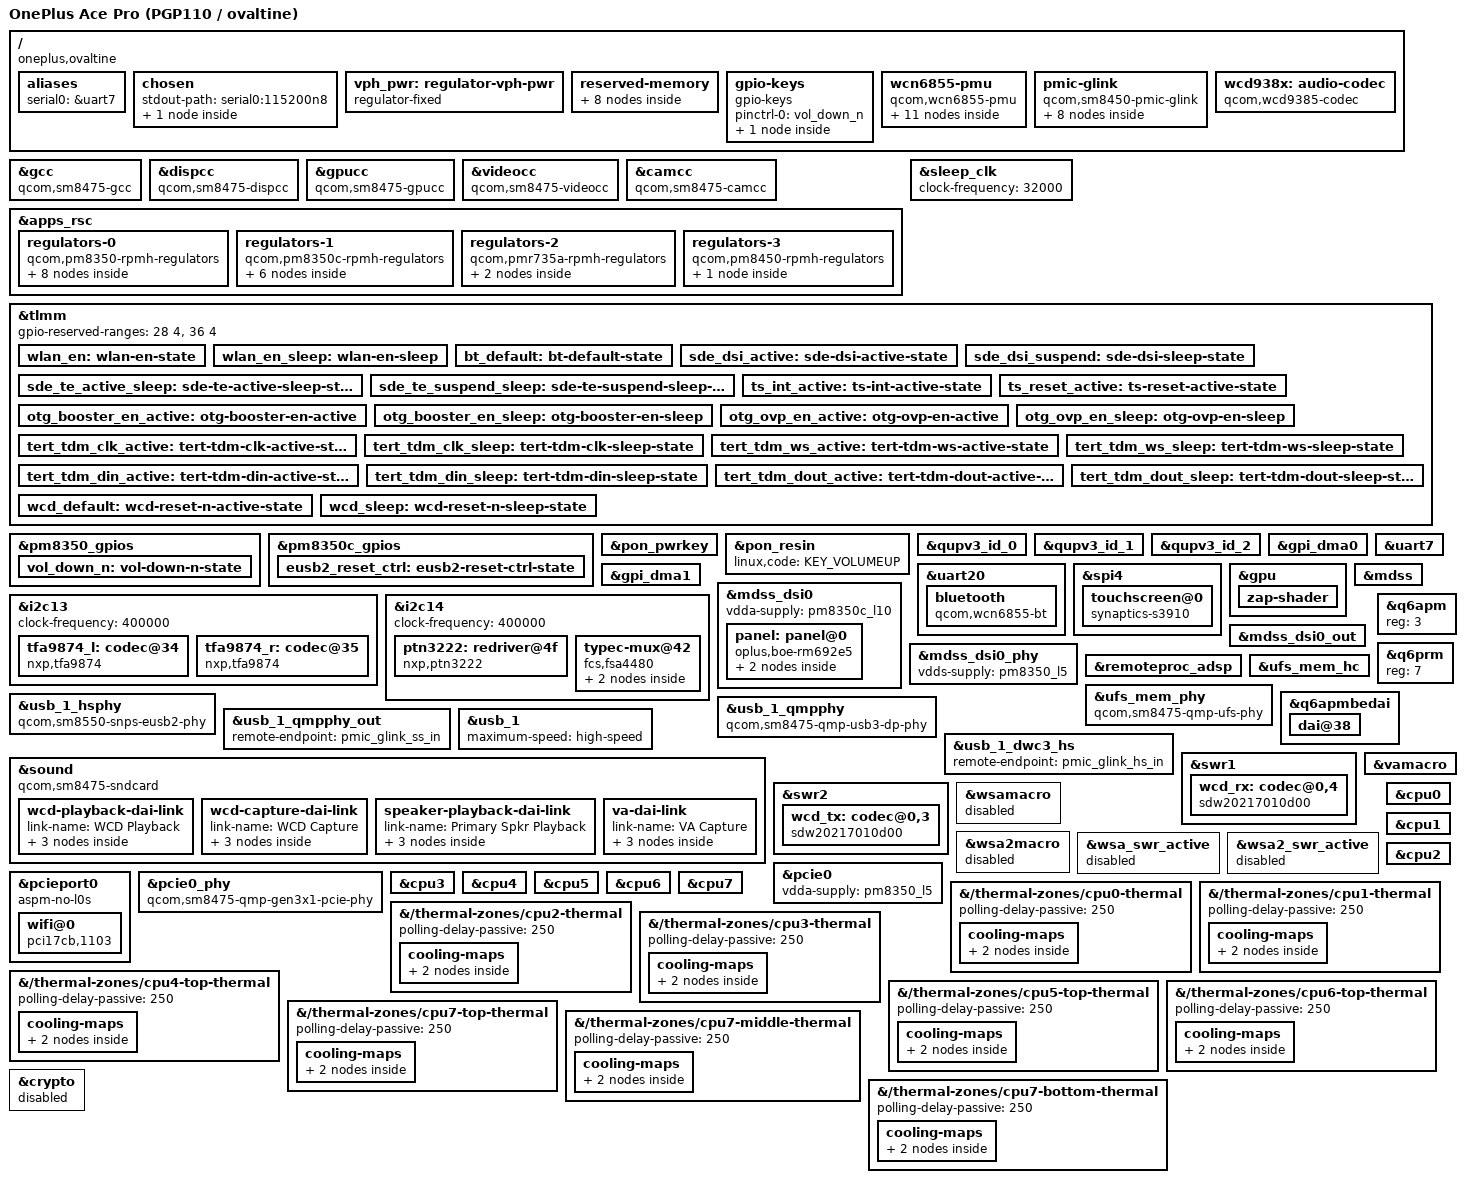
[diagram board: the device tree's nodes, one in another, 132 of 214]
// SPDX-License-Identifier: GPL-2.0-only
/*
 * P1 mainline Device Tree for OnePlus Ace Pro (PGP110 / ovaltine, SM8475).
 */

/dts-v1/;

#include <dt-bindings/arm/qcom,ids.h>
#include <dt-bindings/gpio/gpio.h>
#include <dt-bindings/input/linux-event-codes.h>
#include <dt-bindings/interrupt-controller/irq.h>
#include <dt-bindings/pinctrl/qcom,pmic-gpio.h>
#include <dt-bindings/regulator/qcom,rpmh-regulator.h>

#include "sm8450.dtsi"
#include "pm8350.dtsi"
#include "pm8350b.dtsi"
#include "pm8350c.dtsi"
#include "pm8450.dtsi"
#include "pmk8350.dtsi"
#include "pmr735a.dtsi"

/delete-node/ &cdsp_secure_heap;
/delete-node/ &video_mem;
/delete-node/ &adsp_mem;
/delete-node/ &slpi_mem;
/delete-node/ &rmtfs_mem;

/ {
	model = "OnePlus Ace Pro (PGP110 / ovaltine)";
	compatible = "oneplus,ovaltine", "qcom,sm8475", "qcom,sm8450";
	chassis-type = "handset";

	/* ABL board matching IDs (also provided in sm8475-ovaltine.dtbo) */
	qcom,msm-id = <0x213 0x10000 0x21c 0x10000 0x212 0x10000>;
	qcom,board-id = <0x10008 0x00>;
	oplus,project-id = <0x5552 0x5551>;
	oplus,region-id = <0x01 0x02>;

	aliases {
		serial0 = &uart7;
	};

	chosen {
		#address-cells = <2>;
		#size-cells = <2>;
		ranges;

		stdout-path = "serial0:115200n8";

		framebuffer: framebuffer@b8000000 {
			compatible = "simple-framebuffer";
			reg = <0x0 0xb8000000 0x0 0x2b00000>;
			width = <1080>;
			height = <2412>;
			stride = <(1080 * 4)>;
			format = "a8r8g8b8";
		};
	};

	vph_pwr: regulator-vph-pwr {
		compatible = "regulator-fixed";
		regulator-name = "vph_pwr";
		regulator-min-microvolt = <3700000>;
		regulator-max-microvolt = <3700000>;
		regulator-always-on;
		regulator-boot-on;
	};

	reserved-memory {
		cdsp_secure_heap: memory@80c00000 {
			reg = <0x0 0x80c00000 0x0 0x100000>;
			no-map;
		};

		adsp_mem: memory@85700000 {
			reg = <0x0 0x85700000 0x0 0x2800000>;
			no-map;
		};

		slpi_mem: memory@87f00000 {
			reg = <0x0 0x87f00000 0x0 0x1a00000>;
			no-map;
		};

		video_mem: memory@9fd00000 {
			reg = <0x0 0x9fd00000 0x0 0x700000>;
			no-map;
		};

		ramoops@a1f00000 {
			compatible = "ramoops";
			reg = <0x0 0xa1f00000 0x0 0x100000>;
			console-size = <0x40000>;
			no-map;
		};

		bootloader_log_mem: memory@a7605000 {
			reg = <0x0 0xa7605000 0x0 0x8000>;
		};

		splash_memory: splash_region@b8000000 {
			reg = <0x0 0xb8000000 0x0 0x2b00000>;
			label = "cont_splash_region";
			no-map;
		};

		rmtfs_mem: memory@e6f00000 {
			compatible = "qcom,rmtfs-mem";
			reg = <0x0 0xe6f00000 0x0 0x280000>;
			no-map;
			qcom,client-id = <1>;
			qcom,vmid = <QCOM_SCM_VMID_MSS_MSA>;
		};
	};

	gpio-keys {
		compatible = "gpio-keys";
		pinctrl-0 = <&vol_down_n>;
		pinctrl-names = "default";

		key-volume-down {
			label = "Volume Down";
			linux,code = <KEY_VOLUMEDOWN>;
			gpios = <&pm8350_gpios 6 GPIO_ACTIVE_LOW>;
			debounce-interval = <15>;
			linux,can-disable;
			wakeup-source;
		};
	};

	wcn6855-pmu {
		compatible = "qcom,wcn6855-pmu";

		pinctrl-0 = <&wlan_en>, <&bt_default>;
		pinctrl-1 = <&wlan_en_sleep>;
		pinctrl-names = "default", "sleep";

		wlan-enable-gpios = <&tlmm 80 GPIO_ACTIVE_HIGH>;
		bt-enable-gpios = <&tlmm 81 GPIO_ACTIVE_HIGH>;
		swctrl-gpios = <&tlmm 82 GPIO_ACTIVE_HIGH>;
		xo-clk-gpios = <&tlmm 204 GPIO_ACTIVE_HIGH>;

		vddio-supply = <&pm8350_s10>;
		vddaon-supply = <&pmr735a_s2>;
		vddpmu-supply = <&pm8350_s11>;
		vddrfa0p95-supply = <&pm8350_s11>;
		vddrfa1p3-supply = <&pm8350_s12>;
		vddrfa1p9-supply = <&pm8350c_s1>;
		vddpcie1p3-supply = <&pm8350_s12>;
		vddpcie1p9-supply = <&pm8350c_s1>;

		regulators {
			vreg_pmu_rfa_cmn_0p8: ldo0 { regulator-name = "vreg_pmu_rfa_cmn_0p8"; };
			vreg_pmu_aon_0p8: ldo1 { regulator-name = "vreg_pmu_aon_0p8"; };
			vreg_pmu_wlcx_0p8: ldo2 { regulator-name = "vreg_pmu_wlcx_0p8"; };
			vreg_pmu_wlmx_0p8: ldo3 { regulator-name = "vreg_pmu_wlmx_0p8"; };
			vreg_pmu_btcmx_0p8: ldo4 { regulator-name = "vreg_pmu_btcmx_0p8"; };
			vreg_pmu_pcie_1p8: ldo5 { regulator-name = "vreg_pmu_pcie_1p8"; };
			vreg_pmu_pcie_0p9: ldo6 { regulator-name = "vreg_pmu_pcie_0p9"; };
			vreg_pmu_rfa_0p8: ldo7 { regulator-name = "vreg_pmu_rfa_0p8"; };
			vreg_pmu_rfa_1p2: ldo8 { regulator-name = "vreg_pmu_rfa_1p2"; };
			vreg_pmu_rfa_1p7: ldo9 { regulator-name = "vreg_pmu_rfa_1p7"; };
		};
	};

	pmic-glink {
		compatible = "qcom,sm8450-pmic-glink", "qcom,pmic-glink";
		#address-cells = <1>;
		#size-cells = <0>;
		qcom,protection-domain = "tms/servreg", "msm/adsp/charger_pd";
		orientation-gpios = <&tlmm 91 GPIO_ACTIVE_HIGH>;

		/* OTG GPIOs consumed by qcom_battmgr.c */
		qcom,otg-booster-en-gpio = <&tlmm 64 GPIO_ACTIVE_HIGH>;
		qcom,otg-ovp-en-gpio = <&tlmm 57 GPIO_ACTIVE_HIGH>;

		pinctrl-names = "otg_booster_en_active", "otg_booster_en_sleep",
				"otg_ovp_en_active", "otg_ovp_en_sleep";
		pinctrl-0 = <&otg_booster_en_active>;
		pinctrl-1 = <&otg_booster_en_sleep>;
		pinctrl-2 = <&otg_ovp_en_active>;
		pinctrl-3 = <&otg_ovp_en_sleep>;

		connector@0 {
			compatible = "usb-c-connector";
			reg = <0>;
			power-role = "dual";
			data-role = "dual";

			ports {
				#address-cells = <1>;
				#size-cells = <0>;

				port@0 {
					reg = <0>;

					pmic_glink_hs_in: endpoint {
						remote-endpoint = <&usb_1_dwc3_hs>;
					};
				};

				port@1 {
					reg = <1>;

					pmic_glink_ss_in: endpoint {
						remote-endpoint = <&usb_1_qmpphy_out>;
					};
				};

				port@2 {
					reg = <2>;

					pmic_glink_sbu: endpoint {
						remote-endpoint = <&fsa4480_sbu_mux>;
					};
				};
			};
		};
	};

	wcd938x: audio-codec {
		compatible = "qcom,wcd9385-codec";

		pinctrl-names = "default", "sleep";
		pinctrl-0 = <&wcd_default>;
		pinctrl-1 = <&wcd_sleep>;

		qcom,micbias1-microvolt = <2700000>;
		qcom,micbias2-microvolt = <2700000>;
		qcom,micbias3-microvolt = <2700000>;
		qcom,micbias4-microvolt = <1800000>;
		qcom,mbhc-buttons-vthreshold-microvolt = <75000 150000 237000 500000 500000 500000 500000 500000>;
		qcom,mbhc-headset-vthreshold-microvolt = <1700000>;
		qcom,mbhc-headphone-vthreshold-microvolt = <50000>;
		qcom,rx-device = <&wcd_rx>;
		qcom,tx-device = <&wcd_tx>;

		reset-gpios = <&tlmm 43 GPIO_ACTIVE_LOW>;

		vdd-buck-supply = <&pm8350_s10>;
		vdd-rxtx-supply = <&pm8350_s10>;
		vdd-io-supply = <&pm8350_s10>;
		vdd-mic-bias-supply = <&vreg_bob>;

		#sound-dai-cells = <1>;
	};
};

/* SM8475 (4nm) clock controller compatibles */
&gcc {
	compatible = "qcom,sm8475-gcc";
};

&dispcc {
	compatible = "qcom,sm8475-dispcc";
};

&gpucc {
	compatible = "qcom,sm8475-gpucc";
};

&videocc {
	compatible = "qcom,sm8475-videocc";
};

&camcc {
	compatible = "qcom,sm8475-camcc";
};

&apps_rsc {
	regulators-0 {
		compatible = "qcom,pm8350-rpmh-regulators";
		qcom,pmic-id = "b";

		vdd-s1-supply = <&vph_pwr>;
		vdd-s2-supply = <&vph_pwr>;
		vdd-s3-supply = <&vph_pwr>;
		vdd-s4-supply = <&vph_pwr>;
		vdd-s5-supply = <&vph_pwr>;
		vdd-s6-supply = <&vph_pwr>;
		vdd-s7-supply = <&vph_pwr>;
		vdd-s8-supply = <&vph_pwr>;
		vdd-s9-supply = <&vph_pwr>;
		vdd-s10-supply = <&vph_pwr>;
		vdd-s11-supply = <&vph_pwr>;
		vdd-s12-supply = <&vph_pwr>;

		vdd-l1-l4-supply = <&pm8350_s11>;
		vdd-l2-l7-supply = <&vreg_bob>;
		vdd-l3-l5-supply = <&vreg_bob>;
		vdd-l6-l9-l10-supply = <&pm8350_s12>;

		pm8350_s10: smps10 {
			regulator-name = "pm8350_s10";
			regulator-min-microvolt = <1800000>;
			regulator-max-microvolt = <1800000>;
		};

		pm8350_s11: smps11 {
			regulator-name = "pm8350_s11";
			regulator-min-microvolt = <848000>;
			regulator-max-microvolt = <1104000>;
		};

		pm8350_s12: smps12 {
			regulator-name = "pm8350_s12";
			regulator-min-microvolt = <1224000>;
			regulator-max-microvolt = <1400000>;
		};

		pm8350_l1: ldo1 {
			regulator-name = "pm8350_l1";
			regulator-min-microvolt = <912000>;
			regulator-max-microvolt = <920000>;
			regulator-initial-mode = <RPMH_REGULATOR_MODE_HPM>;
		};

		pm8350_l2: ldo2 {
			regulator-name = "pm8350_l2";
			regulator-min-microvolt = <3072000>;
			regulator-max-microvolt = <3072000>;
			regulator-initial-mode = <RPMH_REGULATOR_MODE_HPM>;
		};

		pm8350_l5: ldo5 {
			regulator-name = "pm8350_l5";
			regulator-min-microvolt = <880000>;
			regulator-max-microvolt = <912000>;
			regulator-initial-mode = <RPMH_REGULATOR_MODE_HPM>;
		};

		pm8350_l7: ldo7 {
			regulator-name = "pm8350_l7";
			regulator-min-microvolt = <2504000>;
			regulator-max-microvolt = <2504000>;
			regulator-initial-mode = <RPMH_REGULATOR_MODE_HPM>;
		};

		pm8350_l9: ldo9 {
			regulator-name = "pm8350_l9";
			regulator-min-microvolt = <1200000>;
			regulator-max-microvolt = <1200000>;
			regulator-initial-mode = <RPMH_REGULATOR_MODE_HPM>;
		};
	};

	regulators-1 {
		compatible = "qcom,pm8350c-rpmh-regulators";
		qcom,pmic-id = "c";

		vdd-s1-supply = <&vph_pwr>;
		vdd-s2-supply = <&vph_pwr>;
		vdd-s3-supply = <&vph_pwr>;
		vdd-s4-supply = <&vph_pwr>;
		vdd-s5-supply = <&vph_pwr>;
		vdd-s6-supply = <&vph_pwr>;
		vdd-s7-supply = <&vph_pwr>;
		vdd-s8-supply = <&vph_pwr>;
		vdd-s9-supply = <&vph_pwr>;
		vdd-s10-supply = <&vph_pwr>;

		vdd-l1-l12-supply = <&vreg_bob>;
		vdd-l2-l8-supply = <&vreg_bob>;
		vdd-l3-l4-l5-l7-l13-supply = <&vreg_bob>;
		vdd-l6-l9-l11-supply = <&vreg_bob>;
		vdd-l10-supply = <&pm8350_s12>;

		vdd-bob-supply = <&vph_pwr>;

		pm8350c_s1: smps1 {
			regulator-name = "pm8350c_s1";
			regulator-min-microvolt = <1800000>;
			regulator-max-microvolt = <2024000>;
		};

		vreg_bob: bob {
			regulator-name = "vreg_bob";
			regulator-min-microvolt = <3008000>;
			regulator-max-microvolt = <3960000>;
			regulator-initial-mode = <RPMH_REGULATOR_MODE_AUTO>;
		};

		pm8350c_l3: ldo3 {
			regulator-name = "pm8350c_l3";
			regulator-min-microvolt = <3008000>;
			regulator-max-microvolt = <3008000>;
			regulator-initial-mode = <RPMH_REGULATOR_MODE_HPM>;
		};

		pm8350c_l10: ldo10 {
			regulator-name = "pm8350c_l10";
			regulator-min-microvolt = <1200000>;
			regulator-max-microvolt = <1200000>;
			regulator-initial-mode = <RPMH_REGULATOR_MODE_HPM>;
		};

		pm8350c_l12: ldo12 {
			regulator-name = "pm8350c_l12";
			regulator-min-microvolt = <1800000>;
			regulator-max-microvolt = <1800000>;
			regulator-initial-mode = <RPMH_REGULATOR_MODE_HPM>;
		};

		pm8350c_l13: ldo13 {
			regulator-name = "pm8350c_l13";
			regulator-min-microvolt = <3104000>;
			regulator-max-microvolt = <3104000>;
			regulator-initial-mode = <RPMH_REGULATOR_MODE_HPM>;
		};
	};

	regulators-2 {
		compatible = "qcom,pmr735a-rpmh-regulators";
		qcom,pmic-id = "e";

		vdd-s2-supply = <&vph_pwr>;
		vdd-l7-bob-supply = <&vreg_bob>;

		pmr735a_s2: smps2 {
			regulator-name = "pmr735a_s2";
			regulator-min-microvolt = <500000>;
			regulator-max-microvolt = <1040000>;
		};

		pmr735a_l7: ldo7 {
			regulator-name = "pmr735a_l7";
			regulator-min-microvolt = <2800000>;
			regulator-max-microvolt = <2800000>;
			regulator-always-on;
			regulator-boot-on;
		};
	};

	regulators-3 {
		compatible = "qcom,pm8450-rpmh-regulators";
		qcom,pmic-id = "h";

		vdd-l4-supply = <&vreg_bob>;

		pm8450_l4: ldo4 {
			regulator-name = "pm8450_l4";
			regulator-min-microvolt = <1800000>;
			regulator-max-microvolt = <1800000>;
			regulator-initial-mode = <RPMH_REGULATOR_MODE_HPM>;
		};
	};
};

&sleep_clk {
	clock-frequency = <32000>;
};

&tlmm {
	gpio-reserved-ranges = <28 4>, <36 4>;

	wlan_en: wlan-en-state {
		pins = "gpio80";
		function = "gpio";
		drive-strength = <16>;
		bias-pull-up;
		output-high;
	};

	wlan_en_sleep: wlan-en-sleep {
		pins = "gpio80";
		function = "gpio";
		drive-strength = <2>;
		bias-pull-down;
		output-low;
	};

	bt_default: bt-default-state {
		pins = "gpio81";
		function = "gpio";
		drive-strength = <2>;
		output-low;
	};

	sde_dsi_active: sde-dsi-active-state {
		pins = "gpio3";
		function = "gpio";
		drive-strength = <8>;
		bias-disable;
	};

	sde_dsi_suspend: sde-dsi-sleep-state {
		pins = "gpio3";
		function = "gpio";
		drive-strength = <2>;
		bias-pull-down;
	};

	sde_te_active_sleep: sde-te-active-sleep-state {
		pins = "gpio86";
		function = "mdp_vsync";
		drive-strength = <2>;
		bias-pull-down;
	};

	sde_te_suspend_sleep: sde-te-suspend-sleep-state {
		pins = "gpio86";
		function = "mdp_vsync";
		drive-strength = <2>;
		bias-pull-down;
	};

	ts_int_active: ts-int-active-state {
		pins = "gpio21";
		function = "gpio";
		drive-strength = <8>;
		bias-disable;
		input-enable;
	};

	ts_reset_active: ts-reset-active-state {
		pins = "gpio20";
		function = "gpio";
		drive-strength = <8>;
		bias-disable;
		output-low;
	};

	otg_booster_en_active: otg-booster-en-active {
		pins = "gpio64";
		function = "gpio";
		drive-strength = <2>;
		output-high;
		bias-pull-up;
	};

	otg_booster_en_sleep: otg-booster-en-sleep {
		pins = "gpio64";
		function = "gpio";
		drive-strength = <2>;
		bias-pull-down;
		output-low;
	};

	otg_ovp_en_active: otg-ovp-en-active {
		pins = "gpio57";
		function = "gpio";
		drive-strength = <2>;
		output-high;
		bias-pull-up;
	};

	otg_ovp_en_sleep: otg-ovp-en-sleep {
		pins = "gpio57";
		function = "gpio";
		drive-strength = <2>;
		bias-pull-down;
		output-low;
	};

	tert_tdm_clk_active: tert-tdm-clk-active-state {
		pins = "gpio121";
		function = "mi2s2_sck";
		drive-strength = <6>;
		bias-disable;
		output-high;
	};

	tert_tdm_clk_sleep: tert-tdm-clk-sleep-state {
		pins = "gpio121";
		function = "gpio";
		drive-strength = <2>;
		bias-pull-down;
	};

	tert_tdm_ws_active: tert-tdm-ws-active-state {
		pins = "gpio123";
		function = "mi2s2_ws";
		drive-strength = <8>;
		bias-disable;
		output-high;
	};

	tert_tdm_ws_sleep: tert-tdm-ws-sleep-state {
		pins = "gpio123";
		function = "gpio";
		drive-strength = <2>;
		bias-pull-down;
	};

	tert_tdm_din_active: tert-tdm-din-active-state {
		pins = "gpio122";
		function = "mi2s2_data0";
		drive-strength = <8>;
		bias-disable;
	};

	tert_tdm_din_sleep: tert-tdm-din-sleep-state {
		pins = "gpio122";
		function = "gpio";
		drive-strength = <2>;
		bias-pull-down;
	};

	tert_tdm_dout_active: tert-tdm-dout-active-state {
		pins = "gpio124";
		function = "mi2s2_data1";
		drive-strength = <8>;
		bias-disable;
	};

	tert_tdm_dout_sleep: tert-tdm-dout-sleep-state {
		pins = "gpio124";
		function = "gpio";
		drive-strength = <2>;
		bias-pull-down;
	};

	wcd_default: wcd-reset-n-active-state {
		pins = "gpio43";
		function = "gpio";
		drive-strength = <16>;
		output-high;
	};

	wcd_sleep: wcd-reset-n-sleep-state {
		pins = "gpio43";
		function = "gpio";
		drive-strength = <16>;
		bias-disable;
		output-low;
	};
};

&pm8350_gpios {
	vol_down_n: vol-down-n-state {
		pins = "gpio6";
		function = "normal";
		power-source = <1>;
		bias-pull-up;
	};
};

&pm8350c_gpios {
	eusb2_reset_ctrl: eusb2-reset-ctrl-state {
		pins = "gpio7";
		function = "normal";
		power-source = <1>;
		output-low;
		bias-disable;
	};
};

&pon_pwrkey {
	status = "okay";
};

&pon_resin {
	linux,code = <KEY_VOLUMEUP>;
	status = "okay";
};

&qupv3_id_0 {
	status = "okay";
};

&qupv3_id_1 {
	status = "okay";
};

&qupv3_id_2 {
	status = "okay";
};

&gpi_dma0 {
	status = "okay";
};

&gpi_dma1 {
	status = "okay";
};

&uart7 {
	status = "okay";
};

&uart20 {
	status = "okay";

	bluetooth {
		compatible = "qcom,wcn6855-bt";

		vddrfacmn-supply = <&vreg_pmu_rfa_cmn_0p8>;
		vddaon-supply = <&vreg_pmu_aon_0p8>;
		vddwlcx-supply = <&vreg_pmu_wlcx_0p8>;
		vddwlmx-supply = <&vreg_pmu_wlmx_0p8>;
		vddbtcmx-supply = <&vreg_pmu_btcmx_0p8>;
		vddrfa0p8-supply = <&vreg_pmu_rfa_0p8>;
		vddrfa1p2-supply = <&vreg_pmu_rfa_1p2>;
		vddrfa1p8-supply = <&vreg_pmu_rfa_1p7>;

		max-speed = <3200000>;
	};
};

&spi4 {
	status = "okay";

	touchscreen@0 {
		compatible = "synaptics-s3910";
		reg = <0>;
		spi-max-frequency = <12000000>;

		interrupt-parent = <&tlmm>;
		interrupts = <21 IRQ_TYPE_LEVEL_LOW>;

		reset-gpios = <&tlmm 20 GPIO_ACTIVE_LOW>;
		synaptics,avdd-gpios = <&tlmm 97 GPIO_ACTIVE_HIGH>;

		vdd-supply = <&pm8350c_l3>;
		avdd-supply = <&pm8450_l4>;

		pinctrl-names = "default";
		pinctrl-0 = <&ts_int_active &ts_reset_active>;
	};
};

&i2c13 {
	clock-frequency = <400000>;
	status = "okay";

	tfa9874_l: codec@34 {
		compatible = "nxp,tfa9874";
		reg = <0x34>;
		reset-gpios = <&tlmm 50 GPIO_ACTIVE_HIGH>;
		vdd-supply = <&pm8350_s10>;
		sound-name-prefix = "Speaker Left";
		#sound-dai-cells = <1>;
		sound-channel = <0>;
	};

	tfa9874_r: codec@35 {
		compatible = "nxp,tfa9874";
		reg = <0x35>;
		reset-gpios = <&tlmm 51 GPIO_ACTIVE_HIGH>;
		vdd-supply = <&pm8350_s10>;
		sound-name-prefix = "Speaker Right";
		#sound-dai-cells = <1>;
		sound-channel = <1>;
	};
};

&i2c14 {
	clock-frequency = <400000>;
	status = "okay";

	ptn3222: redriver@4f {
		compatible = "nxp,ptn3222";
		reg = <0x4f>;
		reset-gpios = <&pm8350c_gpios 7 GPIO_ACTIVE_LOW>;
		pinctrl-names = "default";
		pinctrl-0 = <&eusb2_reset_ctrl>;
		vdd3v3-supply = <&pm8350_l2>;
		vdd1v8-supply = <&pm8350_s10>;
		#phy-cells = <0>;
	};

	typec-mux@42 {
		compatible = "fcs,fsa4480";
		reg = <0x42>;

		vcc-supply = <&vreg_bob>;
		mode-switch;
		orientation-switch;

		port {
			fsa4480_sbu_mux: endpoint {
				remote-endpoint = <&pmic_glink_sbu>;
			};
		};
	};
};

&gpu {
	status = "okay";

	zap-shader {
		firmware-name = "qcom/sm8475/oneplus/ovaltine/a730_zap.mdt";
	};
};

&mdss {
	status = "okay";
};

&mdss_dsi0 {
	vdda-supply = <&pm8350c_l10>;
	status = "okay";

	panel: panel@0 {
		compatible = "oplus,boe-rm692e5";
		reg = <0>;

		reset-gpios = <&tlmm 3 GPIO_ACTIVE_LOW>;
		te-gpios = <&tlmm 86 GPIO_ACTIVE_HIGH>;
		vout-gpios = <&tlmm 90 GPIO_ACTIVE_HIGH>;
		vddr-aod-en-gpios = <&tlmm 180 GPIO_ACTIVE_HIGH>;

		pinctrl-names = "default", "sleep";
		pinctrl-0 = <&sde_dsi_active &sde_te_active_sleep>;
		pinctrl-1 = <&sde_dsi_suspend &sde_te_suspend_sleep>;

		vci-supply = <&pm8350c_l13>;
		vddio-supply = <&pm8350c_l12>;

		port {
			panel_in: endpoint {
				remote-endpoint = <&mdss_dsi0_out>;
			};
		};
	};
};

&mdss_dsi0_out {
	data-lanes = <0 1 2 3>;
	remote-endpoint = <&panel_in>;
};

&mdss_dsi0_phy {
	vdds-supply = <&pm8350_l5>;
	status = "okay";
};

&remoteproc_adsp {
	firmware-name = "qcom/sm8475/oneplus/ovaltine/adsp.mdt";
	status = "okay";
};

&ufs_mem_hc {
	status = "okay";

	reset-gpios = <&tlmm 210 GPIO_ACTIVE_LOW>;

	vcc-supply = <&pm8350_l7>;
	vcc-max-microamp = <1100000>;
	vccq-supply = <&pm8350_l9>;
	vccq-max-microamp = <1200000>;
	vdd-hba-supply = <&pm8350_l9>;
};

/* SM8475 QMP UFS PHY v6 */
&ufs_mem_phy {
	compatible = "qcom,sm8475-qmp-ufs-phy";
	reg = <0 0x01d80000 0 0x2000>;
	vdda-phy-supply = <&pm8350_l5>;
	vdda-pll-supply = <&pm8350c_l10>;
	status = "okay";
};

/* SM8475 SNPS eUSB2 PHY + NXP PTN3222 Repeater */
&usb_1_hsphy {
	compatible = "qcom,sm8550-snps-eusb2-phy";
	reg = <0 0x088e3000 0 0x154>;
	clocks = <&rpmhcc RPMH_CXO_CLK>;
	clock-names = "ref";
	resets = <&gcc GCC_QUSB2PHY_PRIM_BCR>;
	vdd-supply = <&pm8350_l5>;
	vdda12-supply = <&pm8350c_l10>;
	phys = <&ptn3222>;
	status = "okay";
};

/* SM8475 QMP USB3/DP Combo PHY */
&usb_1_qmpphy {
	compatible = "qcom,sm8475-qmp-usb3-dp-phy";
	vdda-phy-supply = <&pm8350c_l10>;
	vdda-pll-supply = <&pm8350_l1>;
	status = "okay";
};

&usb_1_qmpphy_out {
	remote-endpoint = <&pmic_glink_ss_in>;
};

&usb_1 {
	maximum-speed = "high-speed";
	status = "okay";
};

&usb_1_dwc3_hs {
	remote-endpoint = <&pmic_glink_hs_in>;
};

&sound {
	compatible = "qcom,sm8475-sndcard";
	pinctrl-names = "default", "sleep";
	pinctrl-0 = <&tert_tdm_clk_active &tert_tdm_ws_active
		     &tert_tdm_din_active &tert_tdm_dout_active>;
	pinctrl-1 = <&tert_tdm_clk_sleep &tert_tdm_ws_sleep
		     &tert_tdm_din_sleep &tert_tdm_dout_sleep>;
	model = "OnePlus-Ace-Pro";

	audio-routing = "AMIC1", "Analog Mic1",
		"AMIC1", "MIC BIAS1",
		"AMIC2", "Analog Mic2",
		"AMIC2", "MIC BIAS2",
		"AMIC4", "Analog Mic4",
		"AMIC4", "MIC BIAS4",
		"AMIC5", "Analog Mic5",
		"AMIC5", "MIC BIAS3",
		"TX DMIC0", "MIC BIAS3",
		"TX DMIC1", "MIC BIAS1",
		"TX DMIC2", "MIC BIAS1",
		"TX DMIC3", "MIC BIAS3",
		"TX DMIC4", "MIC BIAS4",
		"IN1_HPHL", "HPHL_OUT",
		"IN2_HPHR", "HPHR_OUT",
		"IN3_AUX", "AUX_OUT",
		"RX_TX DEC0_INP", "TX DEC0 MUX",
		"RX_TX DEC1_INP", "TX DEC1 MUX",
		"RX_TX DEC2_INP", "TX DEC2 MUX",
		"RX_TX DEC3_INP", "TX DEC3 MUX",
		"TX SWR_INPUT0", "ADC1_OUTPUT",
		"TX SWR_INPUT1", "ADC2_OUTPUT",
		"TX SWR_INPUT0", "ADC3_OUTPUT",
		"TX SWR_INPUT1", "ADC4_OUTPUT",
		"VA_AIF1 CAP", "VA_SWR_CLK",
		"VA_AIF2 CAP", "VA_SWR_CLK",
		"VA_AIF3 CAP", "VA_SWR_CLK",
		"VA DMIC0", "VA MIC BIAS3",
		"VA DMIC1", "VA MIC BIAS1",
		"VA DMIC2", "VA MIC BIAS1",
		"VA DMIC3", "VA MIC BIAS3",
		"VA DMIC4", "VA MIC BIAS4";

	wcd-playback-dai-link {
		link-name = "WCD Playback";

		cpu {
			sound-dai = <&q6apmbedai RX_CODEC_DMA_RX_0>;
		};

		codec {
			sound-dai = <&wcd938x 0>, <&swr1 0>, <&rxmacro 0>;
		};

		platform {
			sound-dai = <&q6apm>;
		};
	};

	wcd-capture-dai-link {
		link-name = "WCD Capture";

		cpu {
			sound-dai = <&q6apmbedai TX_CODEC_DMA_TX_3>;
		};

		codec {
			sound-dai = <&wcd938x 1>, <&swr2 0>, <&txmacro 0>;
		};

		platform {
			sound-dai = <&q6apm>;
		};
	};

	speaker-playback-dai-link {
		link-name = "Primary Spkr Playback";

		cpu {
			sound-dai = <&q6apmbedai TERTIARY_TDM_RX_0>;
			dai-tdm-slot-num = <2>;
			dai-tdm-slot-width = <16>;
			dai-tdm-slot-tx-mask = <1 1>;
		};

		codec {
			sound-dai = <&tfa9874_l 0>, <&tfa9874_r 0>;
		};

		platform {
			sound-dai = <&q6apm>;
		};
	};

	va-dai-link {
		link-name = "VA Capture";

		cpu {
			sound-dai = <&q6apmbedai VA_CODEC_DMA_TX_0>;
		};

		codec {
			sound-dai = <&vamacro 0>;
		};

		platform {
			sound-dai = <&q6apm>;
		};
	};
};

&q6apm {
	reg = <3>;
};

&q6prm {
	reg = <7>;
};

&q6apmbedai {
	#address-cells = <1>;
	#size-cells = <0>;

	dai@38 {
		reg = <TERTIARY_TDM_RX_0>;
		clocks = <&q6prmcc LPASS_CLK_ID_TER_MI2S_IBIT
				   LPASS_CLK_ATTRIBUTE_COUPLE_NO>;
		clock-names = "bclk";
	};
};

&swr1 {
	qcom,din-ports = <1>;
	qcom,ports-sinterval =		/bits/ 16 <0x03 0x3f 0x1f 0x07 0x00 0x18f 0xff>;
	qcom,ports-offset1 =		/bits/ 8 <0x00 0x00 0x0b 0x01 0x00 0x00 0xff>;
	qcom,ports-offset2 =		/bits/ 8 <0x00 0x00 0x0b 0x00 0x00 0x00 0xff>;
	qcom,ports-hstart =		/bits/ 8 <0xff 0x03 0xff 0xff 0xff 0x08 0xff>;
	qcom,ports-hstop =		/bits/ 8 <0xff 0x06 0xff 0xff 0xff 0x08 0xff>;
	qcom,ports-word-length =	/bits/ 8 <0x01 0x07 0x04 0xff 0xff 0x0f 0xff>;
	qcom,ports-block-pack-mode =	/bits/ 8 <0xff 0x00 0x01 0xff 0xff 0x00 0xff>;
	qcom,ports-block-group-count =	/bits/ 8 <0xff 0xff 0xff 0xff 0x00 0x00 0xff>;
	qcom,ports-lane-control =	/bits/ 8 <0x01 0x00 0x00 0x00 0x00 0x00 0xff>;
	status = "okay";

	wcd_rx: codec@0,4 {
		compatible = "sdw20217010d00";
		reg = <0 4>;
		qcom,rx-port-mapping = <1 2 3 4 5>;
	};
};

&swr2 {
	status = "okay";

	wcd_tx: codec@0,3 {
		compatible = "sdw20217010d00";
		reg = <0 3>;
		qcom,tx-port-mapping = <1 1 2 3>;
	};
};

&vamacro {
	vdd-micb-supply = <&pm8350_s10>;
	qcom,dmic-sample-rate = <600000>;
	status = "okay";
};

&wsamacro {
	status = "disabled";
};

&wsa2macro {
	status = "disabled";
};

&wsa_swr_active {
	status = "disabled";
};

&wsa2_swr_active {
	status = "disabled";
};

&pcie0 {
	vdda-supply = <&pm8350_l5>;
	status = "okay";
};

&pcieport0 {
	aspm-no-l0s;

	wifi@0 {
		compatible = "pci17cb,1103";
		reg = <0x10000 0x0 0x0 0x0 0x0>;

		vddrfacmn-supply = <&vreg_pmu_rfa_cmn_0p8>;
		vddaon-supply = <&vreg_pmu_aon_0p8>;
		vddwlcx-supply = <&vreg_pmu_wlcx_0p8>;
		vddwlmx-supply = <&vreg_pmu_wlmx_0p8>;
		vddpcie1p8-supply = <&vreg_pmu_pcie_1p8>;
		vddpcie0p9-supply = <&vreg_pmu_pcie_0p9>;
		vddrfa0p8-supply = <&vreg_pmu_rfa_0p8>;
		vddrfa1p2-supply = <&vreg_pmu_rfa_1p2>;
		vddrfa1p8-supply = <&vreg_pmu_rfa_1p7>;
	};
};

&pcie0_phy {
	compatible = "qcom,sm8475-qmp-gen3x1-pcie-phy";
	vdda-phy-supply = <&pm8350_l5>;
	vdda-pll-supply = <&pm8350c_l10>;
	status = "okay";
};

/*
 * Stock SM8475 Energy Aware Scheduling (EAS) CPU capacities & power model
 * (from stock dtb_1.dts): Silver A510 (0-3), Gold A710 (4-6), Prime X2 (7).
 */
&cpu0 {
	capacity-dmips-mhz = <1024>;
	dynamic-power-coefficient = <100>;
};

&cpu1 {
	capacity-dmips-mhz = <1024>;
	dynamic-power-coefficient = <100>;
};

&cpu2 {
	capacity-dmips-mhz = <1024>;
	dynamic-power-coefficient = <100>;
};

&cpu3 {
	capacity-dmips-mhz = <1024>;
	dynamic-power-coefficient = <100>;
};

&cpu4 {
	capacity-dmips-mhz = <2253>;
	dynamic-power-coefficient = <257>;
};

&cpu5 {
	capacity-dmips-mhz = <2253>;
	dynamic-power-coefficient = <257>;
};

&cpu6 {
	capacity-dmips-mhz = <2253>;
	dynamic-power-coefficient = <257>;
};

&cpu7 {
	capacity-dmips-mhz = <2386>;
	dynamic-power-coefficient = <509>;
};

/* Passive thermal throttling bindings for CPU clusters */
&{/thermal-zones/cpu0-thermal} {
	polling-delay-passive = <250>;

	cooling-maps {
		map0 {
			trip = <&cpu0_alert0>;
			cooling-device = <&cpu0 THERMAL_NO_LIMIT THERMAL_NO_LIMIT>,
					 <&cpu1 THERMAL_NO_LIMIT THERMAL_NO_LIMIT>,
					 <&cpu2 THERMAL_NO_LIMIT THERMAL_NO_LIMIT>,
					 <&cpu3 THERMAL_NO_LIMIT THERMAL_NO_LIMIT>;
		};

		map1 {
			trip = <&cpu0_alert1>;
			cooling-device = <&cpu0 THERMAL_NO_LIMIT THERMAL_NO_LIMIT>,
					 <&cpu1 THERMAL_NO_LIMIT THERMAL_NO_LIMIT>,
					 <&cpu2 THERMAL_NO_LIMIT THERMAL_NO_LIMIT>,
					 <&cpu3 THERMAL_NO_LIMIT THERMAL_NO_LIMIT>;
		};
	};
};

&{/thermal-zones/cpu1-thermal} {
	polling-delay-passive = <250>;

	cooling-maps {
		map0 {
			trip = <&cpu1_alert0>;
			cooling-device = <&cpu0 THERMAL_NO_LIMIT THERMAL_NO_LIMIT>,
					 <&cpu1 THERMAL_NO_LIMIT THERMAL_NO_LIMIT>,
					 <&cpu2 THERMAL_NO_LIMIT THERMAL_NO_LIMIT>,
					 <&cpu3 THERMAL_NO_LIMIT THERMAL_NO_LIMIT>;
		};

		map1 {
			trip = <&cpu1_alert1>;
			cooling-device = <&cpu0 THERMAL_NO_LIMIT THERMAL_NO_LIMIT>,
					 <&cpu1 THERMAL_NO_LIMIT THERMAL_NO_LIMIT>,
					 <&cpu2 THERMAL_NO_LIMIT THERMAL_NO_LIMIT>,
					 <&cpu3 THERMAL_NO_LIMIT THERMAL_NO_LIMIT>;
		};
	};
};

&{/thermal-zones/cpu2-thermal} {
	polling-delay-passive = <250>;

	cooling-maps {
		map0 {
			trip = <&cpu2_alert0>;
			cooling-device = <&cpu0 THERMAL_NO_LIMIT THERMAL_NO_LIMIT>,
					 <&cpu1 THERMAL_NO_LIMIT THERMAL_NO_LIMIT>,
					 <&cpu2 THERMAL_NO_LIMIT THERMAL_NO_LIMIT>,
					 <&cpu3 THERMAL_NO_LIMIT THERMAL_NO_LIMIT>;
		};

		map1 {
			trip = <&cpu2_alert1>;
			cooling-device = <&cpu0 THERMAL_NO_LIMIT THERMAL_NO_LIMIT>,
					 <&cpu1 THERMAL_NO_LIMIT THERMAL_NO_LIMIT>,
					 <&cpu2 THERMAL_NO_LIMIT THERMAL_NO_LIMIT>,
					 <&cpu3 THERMAL_NO_LIMIT THERMAL_NO_LIMIT>;
		};
	};
};

&{/thermal-zones/cpu3-thermal} {
	polling-delay-passive = <250>;

	cooling-maps {
		map0 {
			trip = <&cpu3_alert0>;
			cooling-device = <&cpu0 THERMAL_NO_LIMIT THERMAL_NO_LIMIT>,
					 <&cpu1 THERMAL_NO_LIMIT THERMAL_NO_LIMIT>,
					 <&cpu2 THERMAL_NO_LIMIT THERMAL_NO_LIMIT>,
					 <&cpu3 THERMAL_NO_LIMIT THERMAL_NO_LIMIT>;
		};

		map1 {
			trip = <&cpu3_alert1>;
			cooling-device = <&cpu0 THERMAL_NO_LIMIT THERMAL_NO_LIMIT>,
					 <&cpu1 THERMAL_NO_LIMIT THERMAL_NO_LIMIT>,
					 <&cpu2 THERMAL_NO_LIMIT THERMAL_NO_LIMIT>,
					 <&cpu3 THERMAL_NO_LIMIT THERMAL_NO_LIMIT>;
		};
	};
};

&{/thermal-zones/cpu4-top-thermal} {
	polling-delay-passive = <250>;

	cooling-maps {
		map0 {
			trip = <&cpu4_top_alert0>;
			cooling-device = <&cpu4 THERMAL_NO_LIMIT THERMAL_NO_LIMIT>,
					 <&cpu5 THERMAL_NO_LIMIT THERMAL_NO_LIMIT>,
					 <&cpu6 THERMAL_NO_LIMIT THERMAL_NO_LIMIT>;
		};

		map1 {
			trip = <&cpu4_top_alert1>;
			cooling-device = <&cpu4 THERMAL_NO_LIMIT THERMAL_NO_LIMIT>,
					 <&cpu5 THERMAL_NO_LIMIT THERMAL_NO_LIMIT>,
					 <&cpu6 THERMAL_NO_LIMIT THERMAL_NO_LIMIT>;
		};
	};
};

&{/thermal-zones/cpu5-top-thermal} {
	polling-delay-passive = <250>;

	cooling-maps {
		map0 {
			trip = <&cpu5_top_alert0>;
			cooling-device = <&cpu4 THERMAL_NO_LIMIT THERMAL_NO_LIMIT>,
					 <&cpu5 THERMAL_NO_LIMIT THERMAL_NO_LIMIT>,
					 <&cpu6 THERMAL_NO_LIMIT THERMAL_NO_LIMIT>;
		};

		map1 {
			trip = <&cpu5_top_alert1>;
			cooling-device = <&cpu4 THERMAL_NO_LIMIT THERMAL_NO_LIMIT>,
					 <&cpu5 THERMAL_NO_LIMIT THERMAL_NO_LIMIT>,
					 <&cpu6 THERMAL_NO_LIMIT THERMAL_NO_LIMIT>;
		};
	};
};

&{/thermal-zones/cpu6-top-thermal} {
	polling-delay-passive = <250>;

	cooling-maps {
		map0 {
			trip = <&cpu6_top_alert0>;
			cooling-device = <&cpu4 THERMAL_NO_LIMIT THERMAL_NO_LIMIT>,
					 <&cpu5 THERMAL_NO_LIMIT THERMAL_NO_LIMIT>,
					 <&cpu6 THERMAL_NO_LIMIT THERMAL_NO_LIMIT>;
		};

		map1 {
			trip = <&cpu6_top_alert1>;
			cooling-device = <&cpu4 THERMAL_NO_LIMIT THERMAL_NO_LIMIT>,
					 <&cpu5 THERMAL_NO_LIMIT THERMAL_NO_LIMIT>,
					 <&cpu6 THERMAL_NO_LIMIT THERMAL_NO_LIMIT>;
		};
	};
};

&{/thermal-zones/cpu7-top-thermal} {
	polling-delay-passive = <250>;

	cooling-maps {
		map0 {
			trip = <&cpu7_top_alert0>;
			cooling-device = <&cpu7 THERMAL_NO_LIMIT THERMAL_NO_LIMIT>;
		};

		map1 {
			trip = <&cpu7_top_alert1>;
			cooling-device = <&cpu7 THERMAL_NO_LIMIT THERMAL_NO_LIMIT>;
		};
	};
};

&{/thermal-zones/cpu7-middle-thermal} {
	polling-delay-passive = <250>;

	cooling-maps {
		map0 {
			trip = <&cpu7_middle_alert0>;
			cooling-device = <&cpu7 THERMAL_NO_LIMIT THERMAL_NO_LIMIT>;
		};

		map1 {
			trip = <&cpu7_middle_alert1>;
			cooling-device = <&cpu7 THERMAL_NO_LIMIT THERMAL_NO_LIMIT>;
		};
	};
};

&{/thermal-zones/cpu7-bottom-thermal} {
	polling-delay-passive = <250>;

	cooling-maps {
		map0 {
			trip = <&cpu7_bottom_alert0>;
			cooling-device = <&cpu7 THERMAL_NO_LIMIT THERMAL_NO_LIMIT>;
		};

		map1 {
			trip = <&cpu7_bottom_alert1>;
			cooling-device = <&cpu7 THERMAL_NO_LIMIT THERMAL_NO_LIMIT>;
		};
	};
};

/*
 * Mainline CONFIG_CRYPTO_DEV_QCE is marked BROKEN and unbound on SM8475;
 * keeping crypto@1dfa000 enabled prevents qnoc-sm8450 icc_sync_state(),
 * pinning LLCC/EBI/GEMNOC boot proxy bandwidth at INT_MAX (2147483647).
 */
&crypto {
	status = "disabled";
};
